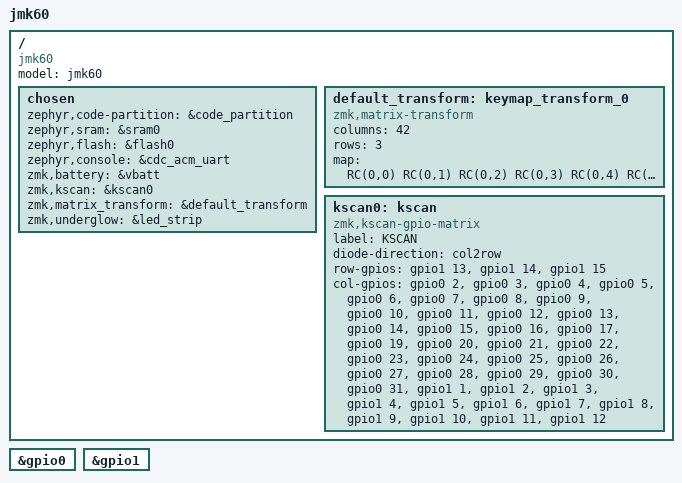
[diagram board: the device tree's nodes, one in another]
/*
 * Copyright (c) 2021 Nick Winans
 *
 * SPDX-License-Identifier: MIT 改名字 
 */

/dts-v1/;
#include <nordic/nrf52840_qiaa.dtsi>

#include <dt-bindings/led/led.h>
#include <dt-bindings/zmk/matrix_transform.h>

/ {
	model = "jmk60";
	compatible = "jmk60";

	chosen {
		zephyr,code-partition = &code_partition;
		zephyr,sram = &sram0;
		zephyr,flash = &flash0;
		zephyr,console = &cdc_acm_uart;
		zmk,battery = &vbatt;
		zmk,kscan = &kscan0;
		zmk,matrix_transform = &default_transform;
		zmk,underglow = &led_strip;
	};

	default_transform: keymap_transform_0 {
		compatible = "zmk,matrix-transform";
		columns = <42>;
		rows = <3>;
		map = <
RC(0,0) RC(0,1) RC(0,2) RC(0,3) RC(0,4) RC(0,5) RC(0,6) RC(0,7) RC(0,8) RC(0,9) RC(0,10) RC(0,11) RC(0,12)   RC(0,13)RC(0,14)RC(0,15)RC(0,16)RC(0,17)RC(0,18)RC(0,19)RC(0,20)RC(0,21)RC(0,22)RC(0,23)RC(0,24)RC(0,25)RC(0,26)RC(0,27)RC(0,28)RC(0,29)RC(0,30)RC(0,31)RC(0,32)RC(0,33)RC(0,34)RC(0,35)RC(0,36)RC(0,37)RC(0,38)RC(0,39)RC(0,40)RC(0,41)
RC(1,0) RC(1,1) RC(1,2) RC(1,3) RC(1,4) RC(1,5) RC(1,6) RC(1,7) RC(1,8) RC(1,9) RC(1,10) RC(1,11) RC(1,12)   RC(1,13)RC(1,14)RC(1,15)RC(1,16)RC(1,17)RC(1,18)RC(1,19)RC(1,20)RC(1,21)RC(1,22)RC(1,23)RC(1,24)RC(1,25)RC(1,26)RC(1,27)RC(1,28)RC(1,29)RC(1,30)RC(1,31)RC(1,32)RC(1,33)RC(1,34)RC(1,35)RC(1,36)RC(1,37)RC(1,38)RC(1,39)RC(1,40)RC(1,41)
RC(2,0) RC(2,1) RC(2,2) RC(2,3) RC(2,4) RC(2,5) RC(2,6) RC(2,7) RC(2,8) RC(2,9) RC(2,10) RC(2,11)RC(2,12)    RC(2,13)RC(2,14)RC(2,15)RC(2,16)RC(2,17)RC(2,18)RC(2,19)RC(2,20)RC(2,21)RC(2,22)RC(2,23)RC(2,24)RC(2,25)RC(2,26)RC(2,27)RC(2,28)RC(2,29)RC(2,30)RC(2,31)RC(2,32)RC(2,33)RC(2,34)RC(2,35)RC(2,36)RC(2,37)RC(2,38)RC(2,39)RC(2,40)RC(2,41)

		>;
	};

	kscan0: kscan {
		compatible = "zmk,kscan-gpio-matrix";
		label = "KSCAN";

		diode-direction = "col2row";
		row-gpios
			= <&gpio1 13 (GPIO_ACTIVE_HIGH | GPIO_PULL_DOWN)>
			, <&gpio1 14 (GPIO_ACTIVE_HIGH | GPIO_PULL_DOWN)>
			, <&gpio1 15 (GPIO_ACTIVE_HIGH | GPIO_PULL_DOWN)>
			;
		col-gpios
			= <&gpio0 2 GPIO_ACTIVE_HIGH>
			, <&gpio0 3 GPIO_ACTIVE_HIGH>
			, <&gpio0 4 GPIO_ACTIVE_HIGH>
			, <&gpio0 5 GPIO_ACTIVE_HIGH>
			, <&gpio0 6 GPIO_ACTIVE_HIGH>
			, <&gpio0 7 GPIO_ACTIVE_HIGH>
			, <&gpio0 8 GPIO_ACTIVE_HIGH>
			, <&gpio0 9 GPIO_ACTIVE_HIGH>
			, <&gpio0 10 GPIO_ACTIVE_HIGH>
			, <&gpio0 11 GPIO_ACTIVE_HIGH>
			, <&gpio0 12 GPIO_ACTIVE_HIGH>
			, <&gpio0 13 GPIO_ACTIVE_HIGH>
			, <&gpio0 14 GPIO_ACTIVE_HIGH>
			, <&gpio0 15 GPIO_ACTIVE_HIGH>
			, <&gpio0 16 GPIO_ACTIVE_HIGH>
			, <&gpio0 17 GPIO_ACTIVE_HIGH>
			
			, <&gpio0 19 GPIO_ACTIVE_HIGH>
			, <&gpio0 20 GPIO_ACTIVE_HIGH>
			, <&gpio0 21 GPIO_ACTIVE_HIGH>
			, <&gpio0 22 GPIO_ACTIVE_HIGH>
			, <&gpio0 23 GPIO_ACTIVE_HIGH>
			, <&gpio0 24 GPIO_ACTIVE_HIGH>
			, <&gpio0 25 GPIO_ACTIVE_HIGH>
			, <&gpio0 26 GPIO_ACTIVE_HIGH>
			, <&gpio0 27 GPIO_ACTIVE_HIGH>
			, <&gpio0 28 GPIO_ACTIVE_HIGH>
			, <&gpio0 29 GPIO_ACTIVE_HIGH>
			, <&gpio0 30 GPIO_ACTIVE_HIGH>
			, <&gpio0 31 GPIO_ACTIVE_HIGH>
			, <&gpio1 1  GPIO_ACTIVE_HIGH>
			, <&gpio1 2  GPIO_ACTIVE_HIGH>
			, <&gpio1 3  GPIO_ACTIVE_HIGH>
			, <&gpio1 4  GPIO_ACTIVE_HIGH>
			, <&gpio1 5  GPIO_ACTIVE_HIGH>
			, <&gpio1 6  GPIO_ACTIVE_HIGH>
			, <&gpio1 7  GPIO_ACTIVE_HIGH>
			, <&gpio1 8  GPIO_ACTIVE_HIGH>
			, <&gpio1 9  GPIO_ACTIVE_HIGH>
			, <&gpio1 10 GPIO_ACTIVE_HIGH>
			, <&gpio1 11 GPIO_ACTIVE_HIGH>
			, <&gpio1 12 GPIO_ACTIVE_HIGH>
			;
	};






};





&gpio0 {
	status = "okay";
};

&gpio1 {
	status = "okay";
};




